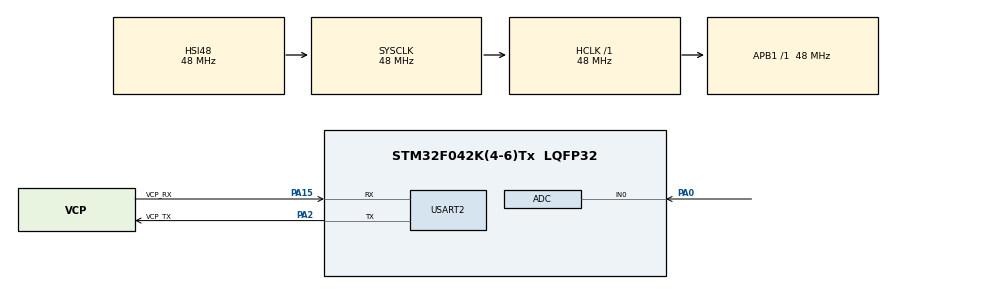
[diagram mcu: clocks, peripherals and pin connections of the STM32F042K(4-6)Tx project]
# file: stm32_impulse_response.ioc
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Mcu.Family=STM32F0
Mcu.Name=STM32F042K(4-6)Tx
Mcu.Package=LQFP32
NVIC.TIM2_IRQn=true\:0\:0\:false\:false\:true\:true\:true\:true
PA0.Mode=IN0
PA0.Signal=ADC_IN0
PA13.GPIO_Label=SWDIO
PA13.Mode=Serial_Wire
PA13.Signal=SYS_SWDIO
PA14.Mode=Serial_Wire
PA14.Signal=SYS_SWCLK
PA15.GPIO_Label=VCP_RX
PA15.Mode=Asynchronous
PA15.Signal=USART2_RX
PA2.GPIO_Label=VCP_TX
PA2.Mode=Asynchronous
PA2.Signal=USART2_TX
PF0-OSC_IN.GPIO_Label=MCO
PF0-OSC_IN.Mode=HSE-External-Oscillator
PF0-OSC_IN.Signal=RCC_OSC_IN
PF1-OSC_OUT.Mode=HSE-External-Oscillator
PF1-OSC_OUT.Signal=RCC_OSC_OUT
ProjectManager.HeapSize=0x200
ProjectManager.StackSize=0x400
ProjectManager.TargetToolchain=Makefile
RCC.AHBFreq_Value=48000000
RCC.APB1Freq_Value=48000000
RCC.APB1TimFreq_Value=48000000
RCC.HCLKFreq_Value=48000000
RCC.SYSCLKFreq_VALUE=48000000
RCC.SYSCLKSource=RCC_SYSCLKSOURCE_HSI48
TIM2.Period=4799
TIM2.Prescaler=9999
USART2.VirtualMode-Asynchronous=VM_ASYNC
VP_TIM2_VS_ClockSourceINT.Mode=Internal
board=NUCLEO-F042K6

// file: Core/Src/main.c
/* USER CODE BEGIN Header */
/**
 ******************************************************************************
 * @file           : main.c
 * @brief          : Main program body
 ******************************************************************************
 * @attention
 *
 * Copyright (c) 2026 STMicroelectronics.
 * All rights reserved.
 *
 * This software is licensed under terms that can be found in the LICENSE file
 * in the root directory of this software component.
 * If no LICENSE file comes with this software, it is provided AS-IS.
 *
 ******************************************************************************
 */
/* USER CODE END Header */
#include "main.h"

/* USER CODE BEGIN Includes */
#include <inttypes.h>
#include <stdint.h>
#include <stdio.h>
/* USER CODE END Includes */

ADC_HandleTypeDef hadc;

TIM_HandleTypeDef htim2;

UART_HandleTypeDef huart2;

void SystemClock_Config(void);
static void MX_GPIO_Init(void);
static void MX_USART2_UART_Init(void);
static void MX_ADC_Init(void);
static void MX_TIM2_Init(void);

/* USER CODE BEGIN 0 */
void HAL_TIM_PeriodElapsedCallback(TIM_HandleTypeDef *htim) {
    HAL_GPIO_TogglePin(GPIOB, GPIO_PIN_3);
}
/* USER CODE END 0 */

int main(void) {

    /* MCU
     * Configuration--------------------------------------------------------*/

    /* Reset of all peripherals, Initializes the Flash interface and the
     * Systick. */
    HAL_Init();

    /* Configure the system clock */
    SystemClock_Config();

    /* Initialize all configured peripherals */
    MX_GPIO_Init();
    MX_USART2_UART_Init();
    MX_ADC_Init();
    MX_TIM2_Init();
    /* USER CODE BEGIN 2 */
    HAL_TIM_Base_Start_IT(&htim2);
    /* USER CODE END 2 */

    /* Infinite loop */
    /* USER CODE BEGIN WHILE */
    uint32_t count = 0;
    while (1) {
        // HAL_GPIO_TogglePin(GPIOB, GPIO_PIN_3);
        printf("here %u\r\n", count);
        ++count;
        HAL_Delay(1000);
        /* USER CODE END WHILE */

    }
}

void SystemClock_Config(void) {
    RCC_OscInitTypeDef RCC_OscInitStruct = {0};
    RCC_ClkInitTypeDef RCC_ClkInitStruct = {0};

    /** Initializes the RCC Oscillators according to the specified parameters
     * in the RCC_OscInitTypeDef structure.
     */
    RCC_OscInitStruct.OscillatorType =
        RCC_OSCILLATORTYPE_HSI14 | RCC_OSCILLATORTYPE_HSI48;
    RCC_OscInitStruct.HSI48State = RCC_HSI48_ON;
    RCC_OscInitStruct.HSI14State = RCC_HSI14_ON;
    RCC_OscInitStruct.HSI14CalibrationValue = 16;
    RCC_OscInitStruct.PLL.PLLState = RCC_PLL_NONE;
    if (HAL_RCC_OscConfig(&RCC_OscInitStruct) != HAL_OK) {
        Error_Handler();
    }

    /** Initializes the CPU, AHB and APB buses clocks
     */
    RCC_ClkInitStruct.ClockType =
        RCC_CLOCKTYPE_HCLK | RCC_CLOCKTYPE_SYSCLK | RCC_CLOCKTYPE_PCLK1;
    RCC_ClkInitStruct.SYSCLKSource = RCC_SYSCLKSOURCE_HSI48;
    RCC_ClkInitStruct.AHBCLKDivider = RCC_SYSCLK_DIV1;
    RCC_ClkInitStruct.APB1CLKDivider = RCC_HCLK_DIV1;

    if (HAL_RCC_ClockConfig(&RCC_ClkInitStruct, FLASH_LATENCY_1) != HAL_OK) {
        Error_Handler();
    }
}

static void MX_ADC_Init(void) {

    ADC_ChannelConfTypeDef sConfig = {0};

    /** Configure the global features of the ADC (Clock, Resolution, Data
     * Alignment and number of conversion)
     */
    hadc.Instance = ADC1;
    hadc.Init.ClockPrescaler = ADC_CLOCK_ASYNC_DIV1;
    hadc.Init.Resolution = ADC_RESOLUTION_12B;
    hadc.Init.DataAlign = ADC_DATAALIGN_RIGHT;
    hadc.Init.ScanConvMode = ADC_SCAN_DIRECTION_FORWARD;
    hadc.Init.EOCSelection = ADC_EOC_SINGLE_CONV;
    hadc.Init.LowPowerAutoWait = DISABLE;
    hadc.Init.LowPowerAutoPowerOff = DISABLE;
    hadc.Init.ContinuousConvMode = DISABLE;
    hadc.Init.DiscontinuousConvMode = DISABLE;
    hadc.Init.ExternalTrigConv = ADC_SOFTWARE_START;
    hadc.Init.ExternalTrigConvEdge = ADC_EXTERNALTRIGCONVEDGE_NONE;
    hadc.Init.DMAContinuousRequests = DISABLE;
    hadc.Init.Overrun = ADC_OVR_DATA_PRESERVED;
    if (HAL_ADC_Init(&hadc) != HAL_OK) {
        Error_Handler();
    }

    /** Configure for the selected ADC regular channel to be converted.
     */
    sConfig.Channel = ADC_CHANNEL_0;
    sConfig.Rank = ADC_RANK_CHANNEL_NUMBER;
    sConfig.SamplingTime = ADC_SAMPLETIME_1CYCLE_5;
    if (HAL_ADC_ConfigChannel(&hadc, &sConfig) != HAL_OK) {
        Error_Handler();
    }
}

static void MX_TIM2_Init(void) {

    TIM_ClockConfigTypeDef sClockSourceConfig = {0};
    TIM_MasterConfigTypeDef sMasterConfig = {0};

    htim2.Instance = TIM2;
    htim2.Init.Prescaler = 9999;
    htim2.Init.CounterMode = TIM_COUNTERMODE_UP;
    htim2.Init.Period = 4799;
    htim2.Init.ClockDivision = TIM_CLOCKDIVISION_DIV1;
    htim2.Init.AutoReloadPreload = TIM_AUTORELOAD_PRELOAD_DISABLE;
    if (HAL_TIM_Base_Init(&htim2) != HAL_OK) {
        Error_Handler();
    }
    sClockSourceConfig.ClockSource = TIM_CLOCKSOURCE_INTERNAL;
    if (HAL_TIM_ConfigClockSource(&htim2, &sClockSourceConfig) != HAL_OK) {
        Error_Handler();
    }
    sMasterConfig.MasterOutputTrigger = TIM_TRGO_RESET;
    sMasterConfig.MasterSlaveMode = TIM_MASTERSLAVEMODE_DISABLE;
    if (HAL_TIMEx_MasterConfigSynchronization(&htim2, &sMasterConfig) !=
        HAL_OK) {
        Error_Handler();
    }
}

static void MX_USART2_UART_Init(void) {

    huart2.Instance = USART2;
    huart2.Init.BaudRate = 38400;
    huart2.Init.WordLength = UART_WORDLENGTH_8B;
    huart2.Init.StopBits = UART_STOPBITS_1;
    huart2.Init.Parity = UART_PARITY_NONE;
    huart2.Init.Mode = UART_MODE_TX_RX;
    huart2.Init.HwFlowCtl = UART_HWCONTROL_NONE;
    huart2.Init.OverSampling = UART_OVERSAMPLING_16;
    huart2.Init.OneBitSampling = UART_ONE_BIT_SAMPLE_DISABLE;
    huart2.AdvancedInit.AdvFeatureInit = UART_ADVFEATURE_NO_INIT;
    if (HAL_UART_Init(&huart2) != HAL_OK) {
        Error_Handler();
    }
}

static void MX_GPIO_Init(void) {
    /* USER CODE BEGIN MX_GPIO_Init_1 */
    GPIO_InitTypeDef GPIO_InitStruct = {0};
    /* USER CODE END MX_GPIO_Init_1 */

    /* GPIO Ports Clock Enable */
    __HAL_RCC_GPIOF_CLK_ENABLE();
    __HAL_RCC_GPIOA_CLK_ENABLE();

    /* USER CODE BEGIN MX_GPIO_Init_2 */
    __HAL_RCC_GPIOB_CLK_ENABLE();

    HAL_GPIO_WritePin(GPIOB, GPIO_PIN_3, GPIO_PIN_RESET);

    GPIO_InitStruct.Pin = GPIO_PIN_3;
    GPIO_InitStruct.Mode = GPIO_MODE_OUTPUT_PP;
    GPIO_InitStruct.Pull = GPIO_NOPULL;
    GPIO_InitStruct.Speed = GPIO_SPEED_FREQ_LOW;
    HAL_GPIO_Init(GPIOB, &GPIO_InitStruct);
    /* USER CODE END MX_GPIO_Init_2 */
}

/* USER CODE BEGIN 4 */

int __io_putchar(int ch) {
    HAL_UART_Transmit(&huart2, (uint8_t *)&ch, 1, HAL_MAX_DELAY);
    return ch;
}

/* USER CODE END 4 */

void Error_Handler(void) {
    /* USER CODE BEGIN Error_Handler_Debug */
    /* User can add his own implementation to report the HAL error return state
     */
    __disable_irq();
    while (1) {
    }
    /* USER CODE END Error_Handler_Debug */
}
#ifdef USE_FULL_ASSERT
/**
 * @brief  Reports the name of the source file and the source line number
 *         where the assert_param error has occurred.
 * @param  file: pointer to the source file name
 * @param  line: assert_param error line source number
 * @retval None
 */
void assert_failed(uint8_t *file, uint32_t line) {
    /* USER CODE BEGIN 6 */
    /* User can add his own implementation to report the file name and line
       number, printf("Wrong parameters value: file %s on line %d\r\n", file,
       line) */
    /* USER CODE END 6 */
}
#endif /* USE_FULL_ASSERT */
